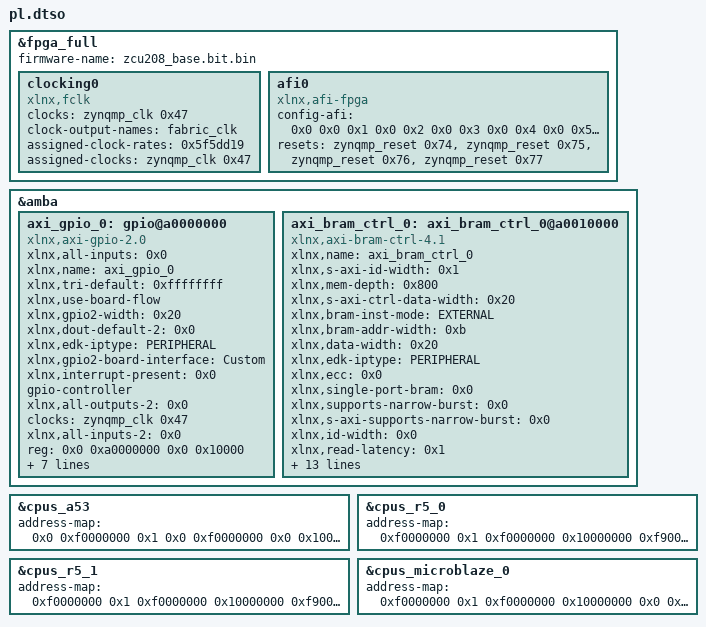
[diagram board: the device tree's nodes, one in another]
/dts-v1/;
/plugin/;

&fpga_full {
        firmware-name = "zcu208_base.bit.bin";

        clocking0: clocking0 {
                clocks = <&zynqmp_clk 0x47>;
                clock-output-names = "fabric_clk";
                #clock-cells = <0x0>;
                assigned-clock-rates = <0x5f5dd19>;
                assigned-clocks = <&zynqmp_clk 0x47>;
                compatible = "xlnx,fclk";
        };

        afi0: afi0 {
                config-afi = <0x0 0x0 0x1 0x0 0x2 0x0 0x3 0x0 0x4 0x0 0x5 0x0 0x6 0x0 0x7 0x0 0x8 0x0 0x9 0x0 0xa 0x0 0xb 0x0 0xc 0x0 0xd 0x0 0xe 0xa00 0xf 0x0>;
                resets = <&zynqmp_reset 0x74>,
                 <&zynqmp_reset 0x75>,
                 <&zynqmp_reset 0x76>,
                 <&zynqmp_reset 0x77>;
                compatible = "xlnx,afi-fpga";
        };
};

&amba {

        axi_gpio_0: gpio@a0000000 {
                xlnx,all-inputs = <0x0>;
                xlnx,name = "axi_gpio_0";
                xlnx,tri-default = <0xffffffff>;
                xlnx,use-board-flow;
                clock-names = "s_axi_aclk";
                xlnx,gpio2-width = <0x20>;
                xlnx,dout-default-2 = <0x0>;
                xlnx,edk-iptype = "PERIPHERAL";
                xlnx,gpio2-board-interface = "Custom";
                xlnx,interrupt-present = <0x0>;
                device_type = "gpio";
                gpio-controller;
                xlnx,all-outputs-2 = <0x0>;
                clocks = <&zynqmp_clk 0x47>;
                xlnx,all-inputs-2 = <0x0>;
                reg = <0x0 0xa0000000 0x0 0x10000>;
                xlnx,tri-default-2 = <0xffffffff>;
                xlnx,ip-name = "axi_gpio";
                xlnx,is-dual = <0x0>;
                xlnx,dout-default = <0x0>;
                xlnx,gpio-width = <0x8>;
                #gpio-cells = <0x2>;
                xlnx,all-outputs = <0x1>;
                compatible = "xlnx,axi-gpio-2.0", "xlnx,xps-gpio-1.00.a";
                xlnx,gpio-board-interface = "led_8bits";
        };

        axi_bram_ctrl_0: axi_bram_ctrl_0@a0010000 {
                xlnx,name = "axi_bram_ctrl_0";
                xlnx,s-axi-id-width = <0x1>;
                xlnx,mem-depth = <0x800>;
                xlnx,s-axi-ctrl-data-width = <0x20>;
                xlnx,bram-inst-mode = "EXTERNAL";
                xlnx,bram-addr-width = <0xb>;
                xlnx,data-width = <0x20>;
                clock-names = "s_axi_aclk";
                xlnx,edk-iptype = "PERIPHERAL";
                xlnx,ecc = <0x0>;
                xlnx,single-port-bram = <0x0>;
                xlnx,supports-narrow-burst = <0x0>;
                xlnx,s-axi-supports-narrow-burst = <0x0>;
                xlnx,id-width = <0x0>;
                xlnx,read-latency = <0x1>;
                xlnx,s-axi-ctrl-addr-width = <0x20>;
                clocks = <&zynqmp_clk 0x47>;
                xlnx,bmg-instance = "EXTERNAL";
                reg = <0x0 0xa0010000 0x0 0x2000>;
                xlnx,ip-name = "axi_bram_ctrl";
                xlnx,fault-inject = <0x0>;
                xlnx,use-ecc = <0x0>;
                xlnx,memory-depth = <0x800>;
                xlnx,rd-cmd-optimization = <0x0>;
                xlnx,ecc-type = <0x0>;
                xlnx,ecc-onoff-reset-value = <0x0>;
                compatible = "xlnx,axi-bram-ctrl-4.1", "xlnx,axi-bram-ctrl";
                xlnx,edk-special = "BRAM_CTRL";
                xlnx,protocol = "AXI4";
        };
};

&cpus_a53 {
        address-map = <0x0 0xf0000000 0x1 0x0 0xf0000000 0x0 0x10000000 0x0 0xf9000000 0x2 0x0 0xf9000000 0x0 0x80000 0x0 0x0 0x3 0x0 0x0 0x0 0x0 0x0 0x0 0x4 0x0 0x0 0x0 0x0 0x0 0xffa50800 0x5 0x0 0xffa50800 0x0 0x400 0x0 0xffa50c00 0x6 0x0 0xffa50c00 0x0 0x400 0x0 0xa0010000 0x7 0x0 0xa0010000 0x0 0x2000 0x0 0xa0010000 0x8 0x0 0xa0010000 0x0 0x2000 0x0 0xfffc0000 0x9 0x0 0xfffc0000 0x0 0x40000 0x0 0xff300000 0xa 0x0 0xff300000 0x0 0x10000 0x0 0x0 0xb 0x0 0x0 0x0 0x7ff00000 0x8 0x0 0xc 0x8 0x0 0x0 0x80000000 0x0 0xa0000000 0xd 0x0 0xa0000000 0x0 0x10000 0x0 0xf9010000 0xe 0x0 0xf9010000 0x0 0x70000 0x0 0xffa80000 0xf 0x0 0xffa80000 0x0 0x10000 0x0 0xffa90000 0x10 0x0 0xffa90000 0x0 0x10000 0x0 0xffaa0000 0x11 0x0 0xffaa0000 0x0 0x10000 0x0 0xffab0000 0x12 0x0 0xffab0000 0x0 0x10000 0x0 0xffac0000 0x13 0x0 0xffac0000 0x0 0x10000 0x0 0xffad0000 0x14 0x0 0xffad0000 0x0 0x10000 0x0 0xffae0000 0x15 0x0 0xffae0000 0x0 0x10000 0x0 0xffaf0000 0x16 0x0 0xffaf0000 0x0 0x10000 0x0 0xfd360000 0x17 0x0 0xfd360000 0x0 0x10000 0x0 0xfd370000 0x18 0x0 0xfd370000 0x0 0x10000 0x0 0xfd380000 0x19 0x0 0xfd380000 0x0 0x10000 0x0 0xfd390000 0x1a 0x0 0xfd390000 0x0 0x10000 0x0 0xfd3a0000 0x1b 0x0 0xfd3a0000 0x0 0x10000 0x0 0xfd3b0000 0x1c 0x0 0xfd3b0000 0x0 0x10000 0x0 0xff9b0000 0x1d 0x0 0xff9b0000 0x0 0x10000 0x0 0xffa50000 0x1e 0x0 0xffa50000 0x0 0x10000 0x0 0xfd0b0000 0x1f 0x0 0xfd0b0000 0x0 0x10000 0x0 0xffa00000 0x20 0x0 0xffa00000 0x0 0x10000 0x0 0xffa10000 0x21 0x0 0xffa10000 0x0 0x10000 0x0 0xfd490000 0x22 0x0 0xfd490000 0x0 0x10000 0x0 0xfd5c0000 0x23 0x0 0xfd5c0000 0x0 0x10000 0x0 0xfd6e0000 0x24 0x0 0xfd6e0000 0x0 0x10000 0x0 0xfd5e0000 0x25 0x0 0xfd5e0000 0x0 0x10000 0x0 0xfe800000 0x26 0x0 0xfe800000 0x0 0x800000 0x0 0xfd1a0000 0x27 0x0 0xfd1a0000 0x0 0x140000 0x0 0xff5e0000 0x28 0x0 0xff5e0000 0x0 0x280000 0x0 0xffca0000 0x29 0x0 0xffca0000 0x0 0x10000 0x0 0xffc80000 0x2a 0x0 0xffc80000 0x0 0x20000 0x0 0xff380000 0x2b 0x0 0xff380000 0x0 0x80000 0x0 0xfd080000 0x2c 0x0 0xfd080000 0x0 0x10000 0x0 0xfd090000 0x2d 0x0 0xfd090000 0x0 0x10000 0x0 0xfd000000 0x2e 0x0 0xfd000000 0x0 0x10000 0x0 0xfd010000 0x2f 0x0 0xfd010000 0x0 0x10000 0x0 0xfd020000 0x30 0x0 0xfd020000 0x0 0x10000 0x0 0xfd030000 0x31 0x0 0xfd030000 0x0 0x10000 0x0 0xfd040000 0x32 0x0 0xfd040000 0x0 0x10000 0x0 0xfd050000 0x33 0x0 0xfd050000 0x0 0x10000 0x0 0xfd070000 0x34 0x0 0xfd070000 0x0 0x1000 0x0 0xffcc0000 0x35 0x0 0xffcc0000 0x0 0x10000 0x0 0xff0e0000 0x36 0x0 0xff0e0000 0x0 0x10000 0x0 0xfd700000 0x37 0x0 0xfd700000 0x0 0x100000 0x0 0xfd610000 0x38 0x0 0xfd610000 0x0 0x80000 0x0 0xfd690000 0x39 0x0 0xfd690000 0x0 0x40000 0x0 0xfd5d0000 0x3a 0x0 0xfd5d0000 0x0 0x10000 0x0 0xfd4f0000 0x3b 0x0 0xfd4f0000 0x0 0x10000 0x0 0xfd500000 0x3c 0x0 0xfd500000 0x0 0x10000 0x0 0xfd510000 0x3d 0x0 0xfd510000 0x0 0x10000 0x0 0xfd520000 0x3e 0x0 0xfd520000 0x0 0x10000 0x0 0xfd530000 0x3f 0x0 0xfd530000 0x0 0x10000 0x0 0xfd540000 0x40 0x0 0xfd540000 0x0 0x10000 0x0 0xfd550000 0x41 0x0 0xfd550000 0x0 0x10000 0x0 0xfd560000 0x42 0x0 0xfd560000 0x0 0x10000 0x0 0xfd570000 0x43 0x0 0xfd570000 0x0 0x10000 0x0 0xff0a0000 0x44 0x0 0xff0a0000 0x0 0x10000 0x0 0xff020000 0x45 0x0 0xff020000 0x0 0x10000 0x0 0xff030000 0x46 0x0 0xff030000 0x0 0x10000 0x0 0xff250000 0x47 0x0 0xff250000 0x0 0x10000 0x0 0xff260000 0x48 0x0 0xff260000 0x0 0x10000 0x0 0xff240000 0x49 0x0 0xff240000 0x0 0x10000 0x0 0xff180000 0x4a 0x0 0xff180000 0x0 0xc0000 0x0 0xff410000 0x4b 0x0 0xff410000 0x0 0xa0000 0x0 0xff4b0000 0x4c 0x0 0xff4b0000 0x0 0x30000 0x0 0xff980000 0x4d 0x0 0xff980000 0x0 0x10000 0x0 0xff9c0000 0x4e 0x0 0xff9c0000 0x0 0x10000 0x0 0xffcf0000 0x4f 0x0 0xffcf0000 0x0 0x10000 0x0 0xff990000 0x50 0x0 0xff990000 0x0 0x10000 0x0 0xff960000 0x51 0x0 0xff960000 0x0 0x10000 0x0 0xffa70000 0x52 0x0 0xffa70000 0x0 0x10000 0x0 0xffd80000 0x53 0x0 0xffd80000 0x0 0x40000 0x0 0xff0f0000 0x54 0x0 0xff0f0000 0x0 0x10000 0x0 0xc0000000 0x55 0x0 0xc0000000 0x0 0x20000000 0x0 0xffe00000 0x56 0x0 0xffe00000 0x0 0x10000 0x0 0xffe20000 0x57 0x0 0xffe20000 0x0 0x10000 0x0 0xffe90000 0x58 0x0 0xffe90000 0x0 0x10000 0x0 0xffeb0000 0x59 0x0 0xffeb0000 0x0 0x10000 0x0 0xffe00000 0x5a 0x0 0xffe00000 0x0 0x40000 0x0 0xff9a0000 0x5b 0x0 0xff9a0000 0x0 0x10000 0x0 0xffce0000 0x5c 0x0 0xffce0000 0x0 0x10000 0x0 0xffa60000 0x5d 0x0 0xffa60000 0x0 0x10000 0x0 0xfd0c0000 0x5e 0x0 0xfd0c0000 0x0 0x10000 0x0 0xff170000 0x5f 0x0 0xff170000 0x0 0x10000 0x0 0xfd400000 0x60 0x0 0xfd400000 0x0 0x80000 0x0 0xfd3d0000 0x61 0x0 0xfd3d0000 0x0 0x10000 0x0 0xfd800000 0x62 0x0 0xfd800000 0x0 0x800000 0x0 0xfd5f0000 0x63 0x0 0xfd5f0000 0x0 0x10000 0x0 0xff110000 0x64 0x0 0xff110000 0x0 0x10000 0x0 0xff120000 0x65 0x0 0xff120000 0x0 0x10000 0x0 0xff130000 0x66 0x0 0xff130000 0x0 0x10000 0x0 0xff140000 0x67 0x0 0xff140000 0x0 0x10000 0x0 0xff000000 0x68 0x0 0xff000000 0x0 0x10000 0x0 0xff9d0000 0x69 0x0 0xff9d0000 0x0 0x10000 0x0 0xfe200000 0x6a 0x0 0xfe200000 0x0 0x100000 0x0 0xff150000 0x6b 0x0 0xff150000 0x0 0x10000 0x0 0xfd4d0000 0x6c 0x0 0xfd4d0000 0x0 0x10000>;
};

&cpus_r5_0 {
        address-map = <0xf0000000 0x1 0xf0000000 0x10000000 0xf9000000 0x71 0xf9000000 0x3000 0x0 0x3 0x0 0x0 0xa0010000 0x7 0xa0010000 0x2000 0xa0010000 0x8 0xa0010000 0x2000 0xfffc0000 0x9 0xfffc0000 0x40000 0xff310000 0x72 0xff310000 0x10000 0x100000 0x73 0x100000 0x7fefffff 0xa0000000 0xd 0xa0000000 0x10000 0xffa80000 0xf 0xffa80000 0x10000 0xffa90000 0x10 0xffa90000 0x10000 0xffaa0000 0x11 0xffaa0000 0x10000 0xffab0000 0x12 0xffab0000 0x10000 0xffac0000 0x13 0xffac0000 0x10000 0xffad0000 0x14 0xffad0000 0x10000 0xffae0000 0x15 0xffae0000 0x10000 0xffaf0000 0x16 0xffaf0000 0x10000 0xfd360000 0x17 0xfd360000 0x10000 0xfd370000 0x18 0xfd370000 0x10000 0xfd380000 0x19 0xfd380000 0x10000 0xfd390000 0x1a 0xfd390000 0x10000 0xfd3a0000 0x1b 0xfd3a0000 0x10000 0xfd3b0000 0x1c 0xfd3b0000 0x10000 0xff9b0000 0x1d 0xff9b0000 0x10000 0xffa50000 0x1e 0xffa50000 0x10000 0xfd0b0000 0x1f 0xfd0b0000 0x10000 0xffa00000 0x20 0xffa00000 0x10000 0xffa10000 0x21 0xffa10000 0x10000 0xfd490000 0x22 0xfd490000 0x10000 0xfd5c0000 0x23 0xfd5c0000 0x10000 0xfd6e0000 0x24 0xfd6e0000 0x10000 0xfd5e0000 0x25 0xfd5e0000 0x10000 0xfe800000 0x26 0xfe800000 0x800000 0xfd1a0000 0x27 0xfd1a0000 0x140000 0xff5e0000 0x28 0xff5e0000 0x280000 0xffca0000 0x29 0xffca0000 0x10000 0xffc80000 0x2a 0xffc80000 0x20000 0xff380000 0x2b 0xff380000 0x80000 0xfd080000 0x2c 0xfd080000 0x10000 0xfd090000 0x2d 0xfd090000 0x10000 0xfd000000 0x2e 0xfd000000 0x10000 0xfd010000 0x2f 0xfd010000 0x10000 0xfd020000 0x30 0xfd020000 0x10000 0xfd030000 0x31 0xfd030000 0x10000 0xfd040000 0x32 0xfd040000 0x10000 0xfd050000 0x33 0xfd050000 0x10000 0xfd070000 0x34 0xfd070000 0x1000 0xffcc0000 0x35 0xffcc0000 0x10000 0xff0e0000 0x36 0xff0e0000 0x10000 0xfd700000 0x37 0xfd700000 0x100000 0xfd610000 0x38 0xfd610000 0x80000 0xfd690000 0x39 0xfd690000 0x40000 0xfd5d0000 0x3a 0xfd5d0000 0x10000 0xfd4f0000 0x3b 0xfd4f0000 0x10000 0xfd500000 0x3c 0xfd500000 0x10000 0xfd510000 0x3d 0xfd510000 0x10000 0xfd520000 0x3e 0xfd520000 0x10000 0xfd530000 0x3f 0xfd530000 0x10000 0xfd540000 0x40 0xfd540000 0x10000 0xfd550000 0x41 0xfd550000 0x10000 0xfd560000 0x42 0xfd560000 0x10000 0xfd570000 0x43 0xfd570000 0x10000 0xff0a0000 0x44 0xff0a0000 0x10000 0xff020000 0x45 0xff020000 0x10000 0xff030000 0x46 0xff030000 0x10000 0xff250000 0x47 0xff250000 0x10000 0xff260000 0x48 0xff260000 0x10000 0xff240000 0x49 0xff240000 0x10000 0xff180000 0x4a 0xff180000 0xc0000 0xff410000 0x4b 0xff410000 0xa0000 0xff4b0000 0x4c 0xff4b0000 0x30000 0xff980000 0x4d 0xff980000 0x10000 0xff9c0000 0x4e 0xff9c0000 0x10000 0xffcf0000 0x4f 0xffcf0000 0x10000 0xff990000 0x50 0xff990000 0x10000 0xff960000 0x51 0xff960000 0x10000 0xffa70000 0x52 0xffa70000 0x10000 0xffd80000 0x53 0xffd80000 0x40000 0xff0f0000 0x54 0xff0f0000 0x10000 0xc0000000 0x55 0xc0000000 0x20000000 0xff9a0000 0x5b 0xff9a0000 0x10000 0xffce0000 0x5c 0xffce0000 0x10000 0xffa60000 0x5d 0xffa60000 0x10000 0xfd0c0000 0x5e 0xfd0c0000 0x10000 0xff170000 0x5f 0xff170000 0x10000 0xfd400000 0x60 0xfd400000 0x80000 0xfd3d0000 0x61 0xfd3d0000 0x10000 0xfd800000 0x62 0xfd800000 0x800000 0xfd5f0000 0x63 0xfd5f0000 0x10000 0xff110000 0x64 0xff110000 0x10000 0xff120000 0x65 0xff120000 0x10000 0xff130000 0x66 0xff130000 0x10000 0xff140000 0x67 0xff140000 0x10000 0xff000000 0x68 0xff000000 0x10000 0xff9d0000 0x69 0xff9d0000 0x10000 0xfe200000 0x6a 0xfe200000 0x100000 0xff150000 0x6b 0xff150000 0x10000 0xfd4d0000 0x6c 0xfd4d0000 0x10000 0xffcb0000 0x74 0xffcb0000 0x10000 0x0 0x75 0x0 0x10000 0x20000 0x76 0x20000 0x10000 0x0 0x77 0x0 0x40000 0xf9000000 0x78 0xf9000000 0x10000>;
};

&cpus_r5_1 {
        address-map = <0xf0000000 0x1 0xf0000000 0x10000000 0xf9000000 0x71 0xf9000000 0x3000 0x0 0x3 0x0 0x0 0xa0010000 0x7 0xa0010000 0x2000 0xa0010000 0x8 0xa0010000 0x2000 0xfffc0000 0x9 0xfffc0000 0x40000 0xff320000 0x7a 0xff320000 0x10000 0x100000 0x73 0x100000 0x7fefffff 0xa0000000 0xd 0xa0000000 0x10000 0xffa80000 0xf 0xffa80000 0x10000 0xffa90000 0x10 0xffa90000 0x10000 0xffaa0000 0x11 0xffaa0000 0x10000 0xffab0000 0x12 0xffab0000 0x10000 0xffac0000 0x13 0xffac0000 0x10000 0xffad0000 0x14 0xffad0000 0x10000 0xffae0000 0x15 0xffae0000 0x10000 0xffaf0000 0x16 0xffaf0000 0x10000 0xfd360000 0x17 0xfd360000 0x10000 0xfd370000 0x18 0xfd370000 0x10000 0xfd380000 0x19 0xfd380000 0x10000 0xfd390000 0x1a 0xfd390000 0x10000 0xfd3a0000 0x1b 0xfd3a0000 0x10000 0xfd3b0000 0x1c 0xfd3b0000 0x10000 0xff9b0000 0x1d 0xff9b0000 0x10000 0xffa50000 0x1e 0xffa50000 0x10000 0xfd0b0000 0x1f 0xfd0b0000 0x10000 0xffa00000 0x20 0xffa00000 0x10000 0xffa10000 0x21 0xffa10000 0x10000 0xfd490000 0x22 0xfd490000 0x10000 0xfd5c0000 0x23 0xfd5c0000 0x10000 0xfd6e0000 0x24 0xfd6e0000 0x10000 0xfd5e0000 0x25 0xfd5e0000 0x10000 0xfe800000 0x26 0xfe800000 0x800000 0xfd1a0000 0x27 0xfd1a0000 0x140000 0xff5e0000 0x28 0xff5e0000 0x280000 0xffca0000 0x29 0xffca0000 0x10000 0xffc80000 0x2a 0xffc80000 0x20000 0xff380000 0x2b 0xff380000 0x80000 0xfd080000 0x2c 0xfd080000 0x10000 0xfd090000 0x2d 0xfd090000 0x10000 0xfd000000 0x2e 0xfd000000 0x10000 0xfd010000 0x2f 0xfd010000 0x10000 0xfd020000 0x30 0xfd020000 0x10000 0xfd030000 0x31 0xfd030000 0x10000 0xfd040000 0x32 0xfd040000 0x10000 0xfd050000 0x33 0xfd050000 0x10000 0xfd070000 0x34 0xfd070000 0x1000 0xffcc0000 0x35 0xffcc0000 0x10000 0xff0e0000 0x36 0xff0e0000 0x10000 0xfd700000 0x37 0xfd700000 0x100000 0xfd610000 0x38 0xfd610000 0x80000 0xfd690000 0x39 0xfd690000 0x40000 0xfd5d0000 0x3a 0xfd5d0000 0x10000 0xfd4f0000 0x3b 0xfd4f0000 0x10000 0xfd500000 0x3c 0xfd500000 0x10000 0xfd510000 0x3d 0xfd510000 0x10000 0xfd520000 0x3e 0xfd520000 0x10000 0xfd530000 0x3f 0xfd530000 0x10000 0xfd540000 0x40 0xfd540000 0x10000 0xfd550000 0x41 0xfd550000 0x10000 0xfd560000 0x42 0xfd560000 0x10000 0xfd570000 0x43 0xfd570000 0x10000 0xff0a0000 0x44 0xff0a0000 0x10000 0xff020000 0x45 0xff020000 0x10000 0xff030000 0x46 0xff030000 0x10000 0xff250000 0x47 0xff250000 0x10000 0xff260000 0x48 0xff260000 0x10000 0xff240000 0x49 0xff240000 0x10000 0xff180000 0x4a 0xff180000 0xc0000 0xff410000 0x4b 0xff410000 0xa0000 0xff4b0000 0x4c 0xff4b0000 0x30000 0xff980000 0x4d 0xff980000 0x10000 0xff9c0000 0x4e 0xff9c0000 0x10000 0xffcf0000 0x4f 0xffcf0000 0x10000 0xff990000 0x50 0xff990000 0x10000 0xff960000 0x51 0xff960000 0x10000 0xffa70000 0x52 0xffa70000 0x10000 0xffd80000 0x53 0xffd80000 0x40000 0xff0f0000 0x54 0xff0f0000 0x10000 0xc0000000 0x55 0xc0000000 0x20000000 0xff9a0000 0x5b 0xff9a0000 0x10000 0xffce0000 0x5c 0xffce0000 0x10000 0xffa60000 0x5d 0xffa60000 0x10000 0xfd0c0000 0x5e 0xfd0c0000 0x10000 0xff170000 0x5f 0xff170000 0x10000 0xfd400000 0x60 0xfd400000 0x80000 0xfd3d0000 0x61 0xfd3d0000 0x10000 0xfd800000 0x62 0xfd800000 0x800000 0xfd5f0000 0x63 0xfd5f0000 0x10000 0xff110000 0x64 0xff110000 0x10000 0xff120000 0x65 0xff120000 0x10000 0xff130000 0x66 0xff130000 0x10000 0xff140000 0x67 0xff140000 0x10000 0xff000000 0x68 0xff000000 0x10000 0xff9d0000 0x69 0xff9d0000 0x10000 0xfe200000 0x6a 0xfe200000 0x100000 0xff150000 0x6b 0xff150000 0x10000 0xfd4d0000 0x6c 0xfd4d0000 0x10000 0xffcb0000 0x74 0xffcb0000 0x10000 0xf9000000 0x78 0xf9000000 0x10000 0x0 0x7b 0x0 0x10000 0x20000 0x7c 0x20000 0x10000>;
};

&cpus_microblaze_0 {
        address-map = <0xf0000000 0x1 0xf0000000 0x10000000 0x0 0x3 0x0 0x0 0xa0010000 0x7 0xa0010000 0x2000 0xa0010000 0x8 0xa0010000 0x2000 0xfffc0000 0x9 0xfffc0000 0x40000 0xff330000 0x7d 0xff330000 0x1000 0xff331000 0x7e 0xff331000 0x1000 0xff332000 0x7f 0xff332000 0x1000 0xff333000 0x80 0xff333000 0x1000 0x0 0xb 0x0 0x7ff00000 0x7ff00000 0xb 0x7ff00000 0x100000 0xa0000000 0xd 0xa0000000 0x10000 0xffa80000 0xf 0xffa80000 0x10000 0xffa90000 0x10 0xffa90000 0x10000 0xffaa0000 0x11 0xffaa0000 0x10000 0xffab0000 0x12 0xffab0000 0x10000 0xffac0000 0x13 0xffac0000 0x10000 0xffad0000 0x14 0xffad0000 0x10000 0xffae0000 0x15 0xffae0000 0x10000 0xffaf0000 0x16 0xffaf0000 0x10000 0xfd360000 0x17 0xfd360000 0x10000 0xfd370000 0x18 0xfd370000 0x10000 0xfd380000 0x19 0xfd380000 0x10000 0xfd390000 0x1a 0xfd390000 0x10000 0xfd3a0000 0x1b 0xfd3a0000 0x10000 0xfd3b0000 0x1c 0xfd3b0000 0x10000 0xff9b0000 0x1d 0xff9b0000 0x10000 0xffa50000 0x1e 0xffa50000 0x10000 0xfd0b0000 0x1f 0xfd0b0000 0x10000 0xffa00000 0x20 0xffa00000 0x10000 0xffa10000 0x21 0xffa10000 0x10000 0xfd490000 0x22 0xfd490000 0x10000 0xfd5c0000 0x23 0xfd5c0000 0x10000 0xfd6e0000 0x24 0xfd6e0000 0x10000 0xfd5e0000 0x25 0xfd5e0000 0x10000 0xfd1a0000 0x27 0xfd1a0000 0x140000 0xff5e0000 0x28 0xff5e0000 0x280000 0xffca0000 0x29 0xffca0000 0x10000 0xffc80000 0x2a 0xffc80000 0x20000 0xff380000 0x2b 0xff380000 0x80000 0xfd080000 0x2c 0xfd080000 0x10000 0xfd090000 0x2d 0xfd090000 0x10000 0xfd000000 0x2e 0xfd000000 0x10000 0xfd010000 0x2f 0xfd010000 0x10000 0xfd020000 0x30 0xfd020000 0x10000 0xfd030000 0x31 0xfd030000 0x10000 0xfd040000 0x32 0xfd040000 0x10000 0xfd050000 0x33 0xfd050000 0x10000 0xfd070000 0x34 0xfd070000 0x1000 0xffcc0000 0x35 0xffcc0000 0x10000 0xff0e0000 0x36 0xff0e0000 0x10000 0xfd700000 0x37 0xfd700000 0x100000 0xfd610000 0x38 0xfd610000 0x80000 0xfd690000 0x39 0xfd690000 0x40000 0xfd5d0000 0x3a 0xfd5d0000 0x10000 0xfd4f0000 0x3b 0xfd4f0000 0x10000 0xfd500000 0x3c 0xfd500000 0x10000 0xfd510000 0x3d 0xfd510000 0x10000 0xfd520000 0x3e 0xfd520000 0x10000 0xfd530000 0x3f 0xfd530000 0x10000 0xfd540000 0x40 0xfd540000 0x10000 0xfd550000 0x41 0xfd550000 0x10000 0xfd560000 0x42 0xfd560000 0x10000 0xfd570000 0x43 0xfd570000 0x10000 0xff0a0000 0x44 0xff0a0000 0x10000 0xff020000 0x45 0xff020000 0x10000 0xff030000 0x46 0xff030000 0x10000 0xff250000 0x47 0xff250000 0x10000 0xff260000 0x48 0xff260000 0x10000 0xff240000 0x49 0xff240000 0x10000 0xff180000 0x4a 0xff180000 0xc0000 0xff410000 0x4b 0xff410000 0xa0000 0xff4b0000 0x4c 0xff4b0000 0x30000 0xff980000 0x4d 0xff980000 0x10000 0xff9c0000 0x4e 0xff9c0000 0x10000 0xffcf0000 0x4f 0xffcf0000 0x10000 0xff990000 0x50 0xff990000 0x10000 0xff960000 0x51 0xff960000 0x10000 0xffa70000 0x52 0xffa70000 0x10000 0xffd80000 0x53 0xffd80000 0x40000 0xff0f0000 0x54 0xff0f0000 0x10000 0xc0000000 0x55 0xc0000000 0x20000000 0xffe00000 0x56 0xffe00000 0x10000 0xffe20000 0x57 0xffe20000 0x10000 0xffe90000 0x58 0xffe90000 0x10000 0xffeb0000 0x59 0xffeb0000 0x10000 0xffe00000 0x5a 0xffe00000 0x40000 0xff9a0000 0x5b 0xff9a0000 0x10000 0xffce0000 0x5c 0xffce0000 0x10000 0xffa60000 0x5d 0xffa60000 0x10000 0xfd0c0000 0x5e 0xfd0c0000 0x10000 0xff170000 0x5f 0xff170000 0x10000 0xfd400000 0x60 0xfd400000 0x80000 0xfd3d0000 0x61 0xfd3d0000 0x10000 0xfd800000 0x62 0xfd800000 0x800000 0xfd5f0000 0x63 0xfd5f0000 0x10000 0xff110000 0x64 0xff110000 0x10000 0xff120000 0x65 0xff120000 0x10000 0xff130000 0x66 0xff130000 0x10000 0xff140000 0x67 0xff140000 0x10000 0xff000000 0x68 0xff000000 0x10000 0xff9d0000 0x69 0xff9d0000 0x10000 0xfe200000 0x6a 0xfe200000 0x100000 0xff150000 0x6b 0xff150000 0x10000 0xfd4d0000 0x6c 0xfd4d0000 0x10000 0xffcb0000 0x74 0xffcb0000 0x10000 0xffcd0000 0x81 0xffcd0000 0x10000 0xffd40000 0x82 0xffd40000 0x20000 0xffdc0000 0x83 0xffdc0000 0x20000>;
};

